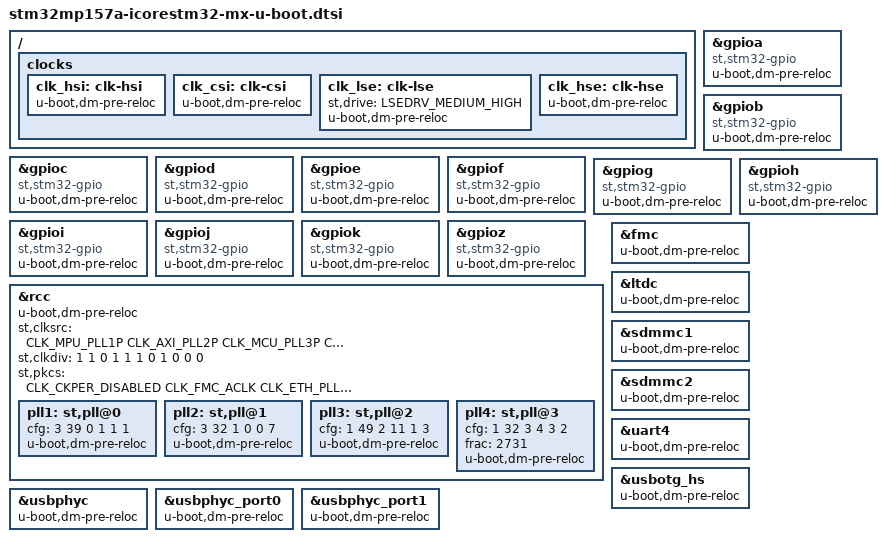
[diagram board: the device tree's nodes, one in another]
/* SPDX-License-Identifier: GPL-2.0+ OR BSD-3-Clause*/
/*
 * Copyright (C) 2019, STMicroelectronics - All Rights Reserved
 * Author: STM32CubeMX code generation for STMicroelectronics.
 */

#include <dt-bindings/clock/stm32mp1-clksrc.h>
#include "stm32mp15-icore-mx.h"

#include "stm32mp157-u-boot.dtsi"
#include "stm32mp15-ddr.dtsi"

/* USER CODE BEGIN includes */
/* USER CODE END includes */

/ {

	/* USER CODE BEGIN root */
	/* USER CODE END root */

clocks {
    /* USER CODE BEGIN clocks */
    /* USER CODE END clocks */

    clk_hsi: clk-hsi {
        /* USER CODE BEGIN clocks */
        /* USER CODE END clocks */
        u-boot,dm-pre-reloc;
    };
    clk_csi: clk-csi {
        /* USER CODE BEGIN clocks */
        /* USER CODE END clocks */
        u-boot,dm-pre-reloc;
    };
    clk_lse: clk-lse {
        /* USER CODE BEGIN clocks */
        /* USER CODE END clocks */
        st,drive=<LSEDRV_MEDIUM_HIGH>;
        u-boot,dm-pre-reloc;
    };
    clk_hse: clk-hse {
        /* USER CODE BEGIN clocks */
        /* USER CODE END clocks */
        u-boot,dm-pre-reloc;
    };
};

}; /*root*/

&gpioa {
    compatible = "st,stm32-gpio";
    u-boot,dm-pre-reloc;
};
&gpiob {
    compatible = "st,stm32-gpio";
    u-boot,dm-pre-reloc;
};
&gpioc {
    compatible = "st,stm32-gpio";
    u-boot,dm-pre-reloc;
};
&gpiod {
    compatible = "st,stm32-gpio";
    u-boot,dm-pre-reloc;
};
&gpioe {
    compatible = "st,stm32-gpio";
    u-boot,dm-pre-reloc;
};
&gpiof {
    compatible = "st,stm32-gpio";
    u-boot,dm-pre-reloc;
};
&gpiog {
    compatible = "st,stm32-gpio";
    u-boot,dm-pre-reloc;
};
&gpioh {
    compatible = "st,stm32-gpio";
    u-boot,dm-pre-reloc;
};
&gpioi {
    compatible = "st,stm32-gpio";
    u-boot,dm-pre-reloc;
};
&gpioj {
    compatible = "st,stm32-gpio";
    u-boot,dm-pre-reloc;
};
&gpiok {
    compatible = "st,stm32-gpio";
    u-boot,dm-pre-reloc;
};
&gpioz {
    compatible = "st,stm32-gpio";
    u-boot,dm-pre-reloc;
};

&rcc {
    u-boot,dm-pre-reloc;
    st,clksrc = <
        CLK_MPU_PLL1P
        CLK_AXI_PLL2P
        CLK_MCU_PLL3P
        CLK_PLL12_HSI
        CLK_PLL3_HSE
        CLK_PLL4_HSE
        CLK_RTC_LSE
        CLK_MCO1_DISABLED
        CLK_MCO2_DISABLED
    >;
    st,clkdiv = <
        1         /*MPU*/
        1         /*AXI*/
        0         /*MCU*/
        1         /*APB1*/
        1         /*APB2*/
        1         /*APB3*/
        0         /*APB4*/
        1         /*APB5*/
        0         /*RTC*/
        0         /*MCO1*/
        0         /*MCO2*/
    >;
    st,pkcs = <
        CLK_CKPER_DISABLED
        CLK_FMC_ACLK
        CLK_ETH_PLL3Q
        CLK_SDMMC12_HSI
        CLK_DSI_DSIPLL
        CLK_STGEN_HSI
        CLK_USBPHY_HSE
        CLK_SPI2S1_DISABLED
        CLK_SPI2S23_DISABLED
        CLK_SPI45_DISABLED
        CLK_SPI6_DISABLED
        CLK_I2C46_CSI
        CLK_SDMMC3_DISABLED
        CLK_USBO_USBPHY
        CLK_ADC_PLL4R
        CLK_CEC_DISABLED
        CLK_I2C12_PCLK1
        CLK_I2C35_DISABLED
        CLK_UART1_DISABLED
        CLK_UART24_HSE
        CLK_UART35_DISABLED
        CLK_UART6_DISABLED
        CLK_UART78_DISABLED
        CLK_SPDIF_DISABLED
        CLK_FDCAN_HSE
        CLK_SAI1_PLL4Q
        CLK_SAI2_PLL3Q
        CLK_SAI3_DISABLED
        CLK_SAI4_DISABLED
        CLK_LPTIM1_DISABLED
        CLK_LPTIM23_DISABLED
        CLK_LPTIM45_DISABLED
    >;
    pll1:st,pll@0 {
        cfg = < 3 39 0 1 1 1>;
        u-boot,dm-pre-reloc;
    };
    pll2:st,pll@1 {
        cfg = < 3 32 1 0 0 7>;
        u-boot,dm-pre-reloc;
    };
    pll3:st,pll@2 {
        cfg = < 1 49 2 11 1 3>;
        u-boot,dm-pre-reloc;
    };
    pll4:st,pll@3 {
        cfg = < 1 32 3 4 3 2>;
        frac = < 2731 >;
        u-boot,dm-pre-reloc;
    };
};

&fmc{
    u-boot,dm-pre-reloc;

    /* USER CODE BEGIN fmc */
    /* USER CODE END fmc */
};

&ltdc{
    u-boot,dm-pre-reloc;

    /* USER CODE BEGIN ltdc */
    /* USER CODE END ltdc */
};

&rcc{
    u-boot,dm-pre-reloc;

    /* USER CODE BEGIN rcc */
    /* USER CODE END rcc */
};

&sdmmc1{
    u-boot,dm-pre-reloc;

    /* USER CODE BEGIN sdmmc1 */
    /* USER CODE END sdmmc1 */
};

&sdmmc2{
    u-boot,dm-pre-reloc;

    /* USER CODE BEGIN sdmmc2 */
    /* USER CODE END sdmmc2 */
};

&uart4{
    u-boot,dm-pre-reloc;

    /* USER CODE BEGIN uart4 */
    /* USER CODE END uart4 */
};

&usbotg_hs{
    u-boot,dm-pre-reloc;

    /* USER CODE BEGIN usbotg_hs */
    /* USER CODE END usbotg_hs */
};

&usbphyc{
    u-boot,dm-pre-reloc;

    /* USER CODE BEGIN usbphyc */
    /* USER CODE END usbphyc */
};

&usbphyc_port0{
    u-boot,dm-pre-reloc;

    /* USER CODE BEGIN usbphyc_port0 */
    /* USER CODE END usbphyc_port0 */
};

&usbphyc_port1{
    u-boot,dm-pre-reloc;

    /* USER CODE BEGIN usbphyc_port1 */
    /* USER CODE END usbphyc_port1 */
};

/* USER CODE BEGIN addons */
/* USER CODE END addons */

